VERSION ""

NS_ :

BS_:

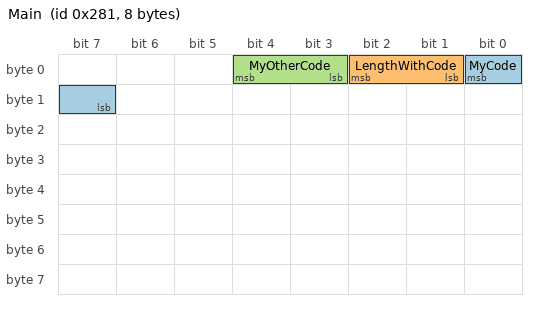
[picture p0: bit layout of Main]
BO_ 641 Main: 8 Vector__XXX
 SG_ MyCode : 0|2@0+ (1,0) [0|3] "" Vector__XXX
 SG_ LengthWithCode : 2|2@0+ (0.5,0) [0|1.5] "" Vector__XXX
 SG_ MyOtherCode : 4|2@0+ (1,0) [0|3] "" Vector__XXX

VAL_ 641 MyCode 0 "ZERO" 1 "ONE" 2 "TWO" 3 "THREE";
VAL_ 641 LengthWithCode 3 "TOO_LONG";
